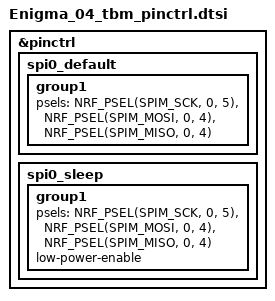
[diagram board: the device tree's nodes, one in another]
&pinctrl {
    spi0_default: spi0_default {
        group1 {
            psels = <NRF_PSEL(SPIM_SCK, 0, 5)>, //SCLK
                    <NRF_PSEL(SPIM_MOSI, 0, 4)>, //SDIO
                    <NRF_PSEL(SPIM_MISO, 0, 4)>; //SDIO
        };
    };

    spi0_sleep: spi0_sleep {
        group1 {
            psels = <NRF_PSEL(SPIM_SCK, 0, 5)>, //SCLK
                    <NRF_PSEL(SPIM_MOSI, 0, 4)>, //SDIO
                    <NRF_PSEL(SPIM_MISO, 0, 4)>; //SDIO
            low-power-enable;
        };
    };
};
